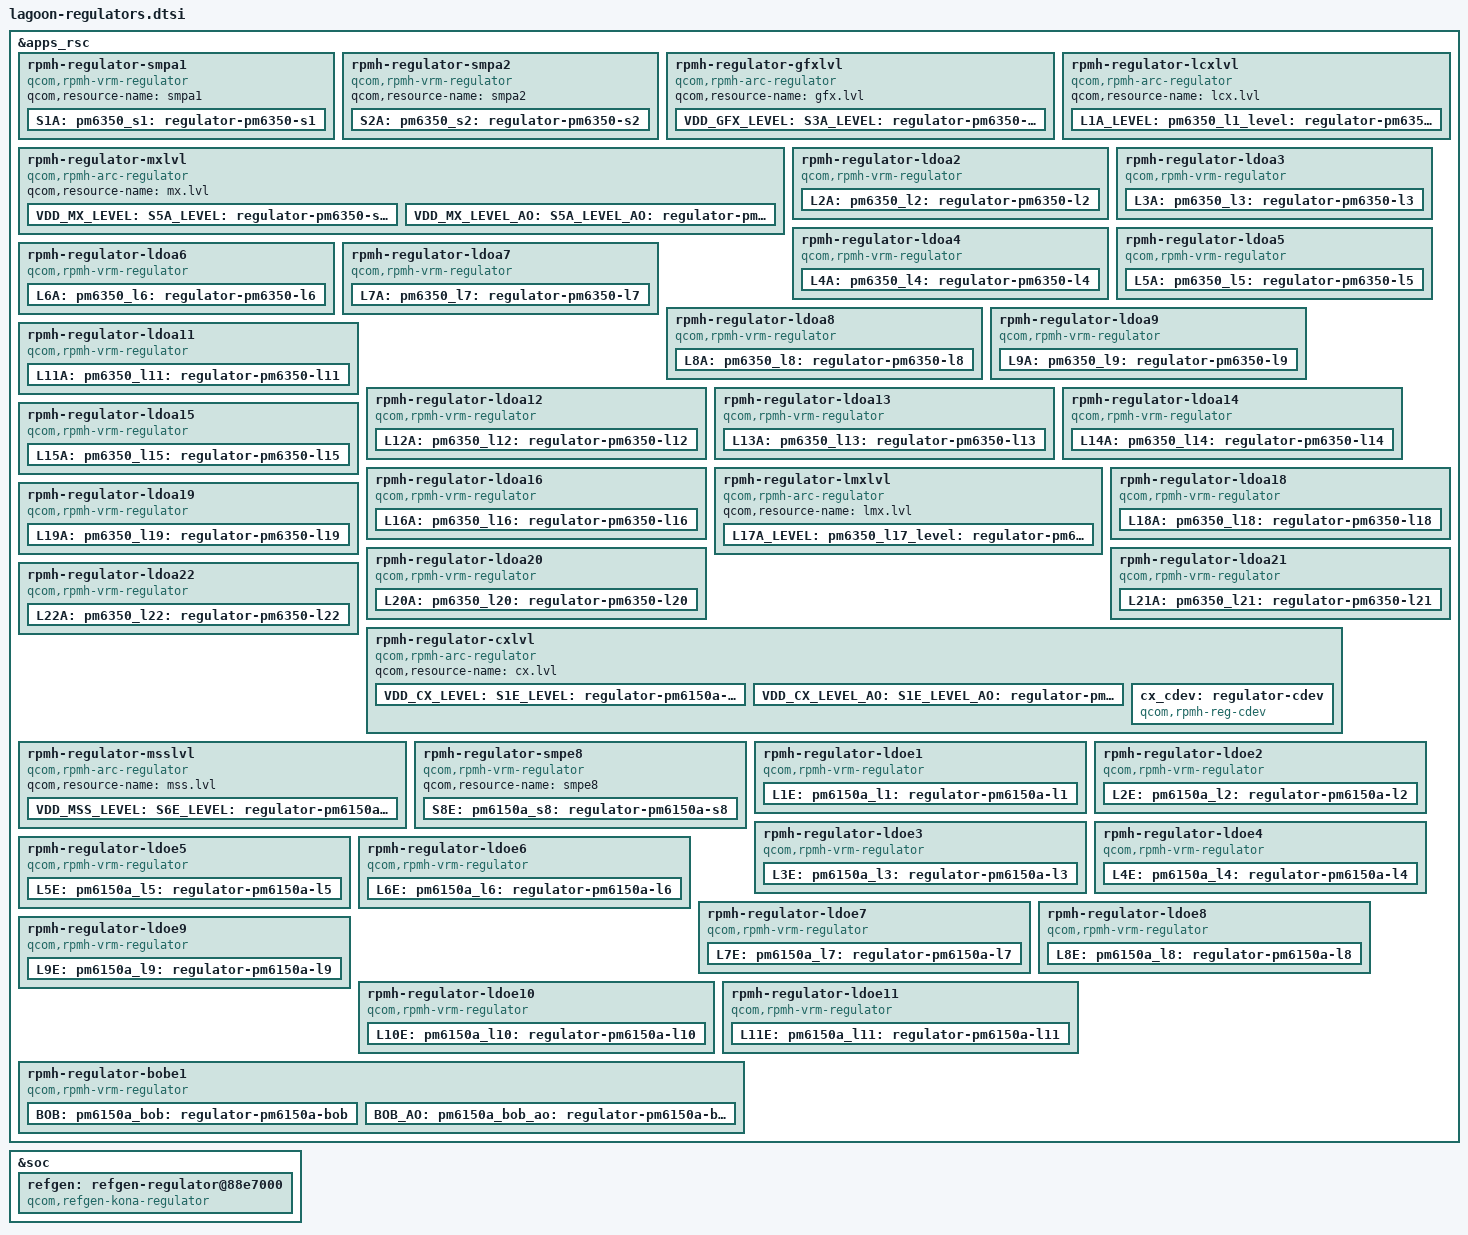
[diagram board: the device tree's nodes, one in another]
#include <dt-bindings/regulator/qcom,rpmh-regulator-levels.h>

&apps_rsc {
	rpmh-regulator-smpa1 {
		compatible = "qcom,rpmh-vrm-regulator";
		qcom,resource-name = "smpa1";
		S1A:
		pm6350_s1: regulator-pm6350-s1 {
			regulator-name = "pm6350_s1";
			qcom,set = <RPMH_REGULATOR_SET_ALL>;
			regulator-min-microvolt = <1000000>;
			regulator-max-microvolt = <1200000>;
			qcom,init-voltage = <1000000>;
		};
	};

	rpmh-regulator-smpa2 {
		compatible = "qcom,rpmh-vrm-regulator";
		qcom,resource-name = "smpa2";
		S2A:
		pm6350_s2: regulator-pm6350-s2 {
			regulator-name = "pm6350_s2";
			qcom,set = <RPMH_REGULATOR_SET_ALL>;
			regulator-min-microvolt = <1503000>;
			regulator-max-microvolt = <2048000>;
			qcom,init-voltage = <1503000>;
		};
	};

	rpmh-regulator-gfxlvl {
		compatible = "qcom,rpmh-arc-regulator";
		qcom,resource-name = "gfx.lvl";
		VDD_GFX_LEVEL:
		S3A_LEVEL:
		pm6350_s3_level: regulator-pm6350-s3-level {
			regulator-name = "pm6350_s3_level";
			qcom,set = <RPMH_REGULATOR_SET_ALL>;
			regulator-min-microvolt =
				<RPMH_REGULATOR_LEVEL_RETENTION>;
			regulator-max-microvolt = <RPMH_REGULATOR_LEVEL_MAX>;
			qcom,init-voltage-level =
				<RPMH_REGULATOR_LEVEL_RETENTION>;
		};
	};

	rpmh-regulator-mxlvl {
		compatible = "qcom,rpmh-arc-regulator";
		qcom,resource-name = "mx.lvl";
		VDD_MX_LEVEL:
		S5A_LEVEL:
		pm6350_s5_level: regulator-pm6350-s5-level {
			regulator-name = "pm6350_s5_level";
			qcom,set = <RPMH_REGULATOR_SET_ALL>;
			regulator-min-microvolt =
				<RPMH_REGULATOR_LEVEL_RETENTION>;
			regulator-max-microvolt = <RPMH_REGULATOR_LEVEL_MAX>;
			qcom,init-voltage-level =
				<RPMH_REGULATOR_LEVEL_RETENTION>;
		};

		VDD_MX_LEVEL_AO:
		S5A_LEVEL_AO:
		pm6350_s5_level_ao: regulator-pm6350-s5-level-ao {
			regulator-name = "pm6350_s5_level_ao";
			qcom,set = <RPMH_REGULATOR_SET_ACTIVE>;
			regulator-min-microvolt =
				<RPMH_REGULATOR_LEVEL_RETENTION>;
			regulator-max-microvolt = <RPMH_REGULATOR_LEVEL_MAX>;
			qcom,init-voltage-level =
				<RPMH_REGULATOR_LEVEL_RETENTION>;
		};
	};

	rpmh-regulator-lcxlvl {
		compatible = "qcom,rpmh-arc-regulator";
		qcom,resource-name = "lcx.lvl";
		L1A_LEVEL:
		pm6350_l1_level: regulator-pm6350-l1-level {
			regulator-name = "pm6350_l1_level";
			qcom,set = <RPMH_REGULATOR_SET_ALL>;
			regulator-min-microvolt =
				<RPMH_REGULATOR_LEVEL_RETENTION>;
			regulator-max-microvolt = <RPMH_REGULATOR_LEVEL_MAX>;
			qcom,init-voltage-level =
				<RPMH_REGULATOR_LEVEL_RETENTION>;
		};
	};

	rpmh-regulator-ldoa2 {
		compatible = "qcom,rpmh-vrm-regulator";
		qcom,resource-name = "ldoa2";
		qcom,regulator-type = "pmic5-ldo";
		qcom,supported-modes =
			<RPMH_REGULATOR_MODE_LPM
			RPMH_REGULATOR_MODE_HPM>;
		qcom,mode-threshold-currents = <0 1>;
		L2A:
		pm6350_l2: regulator-pm6350-l2 {
			regulator-name = "pm6350_l2";
			qcom,set = <RPMH_REGULATOR_SET_ALL>;
			regulator-min-microvolt = <1503000>;
			regulator-max-microvolt = <1980000>;
			qcom,init-voltage = <1503000>;
			qcom,init-mode = <RPMH_REGULATOR_MODE_LPM>;
		};
	};

	rpmh-regulator-ldoa3 {
		compatible = "qcom,rpmh-vrm-regulator";
		qcom,resource-name = "ldoa3";
		qcom,regulator-type = "pmic5-ldo";
		qcom,supported-modes =
			<RPMH_REGULATOR_MODE_LPM
			RPMH_REGULATOR_MODE_HPM>;
		qcom,mode-threshold-currents = <0 1>;
		L3A:
		pm6350_l3: regulator-pm6350-l3 {
			regulator-name = "pm6350_l3";
			qcom,set = <RPMH_REGULATOR_SET_ALL>;
			regulator-min-microvolt = <2700000>;
			regulator-max-microvolt = <3300000>;
			qcom,init-voltage = <2700000>;
			qcom,init-mode = <RPMH_REGULATOR_MODE_LPM>;
		};
	};

	rpmh-regulator-ldoa4 {
		compatible = "qcom,rpmh-vrm-regulator";
		qcom,resource-name = "ldoa4";
		qcom,regulator-type = "pmic5-ldo";
		qcom,supported-modes =
			<RPMH_REGULATOR_MODE_LPM
			RPMH_REGULATOR_MODE_HPM>;
		qcom,mode-threshold-currents = <0 1>;
		L4A:
		pm6350_l4: regulator-pm6350-l4 {
			regulator-name = "pm6350_l4";
			qcom,set = <RPMH_REGULATOR_SET_ALL>;
			regulator-min-microvolt = <352000>;
			regulator-max-microvolt = <801000>;
			qcom,init-voltage = <352000>;
			qcom,init-mode = <RPMH_REGULATOR_MODE_LPM>;
		};
	};

	rpmh-regulator-ldoa5 {
		compatible = "qcom,rpmh-vrm-regulator";
		qcom,resource-name = "ldoa5";
		qcom,regulator-type = "pmic5-ldo";
		qcom,supported-modes =
			<RPMH_REGULATOR_MODE_LPM
			RPMH_REGULATOR_MODE_HPM>;
		qcom,mode-threshold-currents = <0 1>;
		L5A:
		pm6350_l5: regulator-pm6350-l5 {
			regulator-name = "pm6350_l5";
			qcom,set = <RPMH_REGULATOR_SET_ALL>;
			regulator-min-microvolt = <1503000>;
			regulator-max-microvolt = <1980000>;
			qcom,init-voltage = <1503000>;
			qcom,init-mode = <RPMH_REGULATOR_MODE_LPM>;
		};
	};

	rpmh-regulator-ldoa6 {
		compatible = "qcom,rpmh-vrm-regulator";
		qcom,resource-name = "ldoa6";
		qcom,regulator-type = "pmic5-ldo";
		qcom,supported-modes =
			<RPMH_REGULATOR_MODE_LPM
			RPMH_REGULATOR_MODE_HPM>;
		qcom,mode-threshold-currents = <0 1>;
		L6A:
		pm6350_l6: regulator-pm6350-l6 {
			regulator-name = "pm6350_l6";
			qcom,set = <RPMH_REGULATOR_SET_ALL>;
			regulator-min-microvolt = <1710000>;
			regulator-max-microvolt = <3544000>;
			qcom,init-voltage = <1710000>;
			qcom,init-mode = <RPMH_REGULATOR_MODE_LPM>;
		};
	};

	rpmh-regulator-ldoa7 {
		compatible = "qcom,rpmh-vrm-regulator";
		qcom,resource-name = "ldoa7";
		qcom,regulator-type = "pmic5-ldo";
		qcom,supported-modes =
			<RPMH_REGULATOR_MODE_LPM
			RPMH_REGULATOR_MODE_HPM>;
		qcom,mode-threshold-currents = <0 1>;
		L7A:
		pm6350_l7: regulator-pm6350-l7 {
			regulator-name = "pm6350_l7";
			qcom,set = <RPMH_REGULATOR_SET_ALL>;
			regulator-min-microvolt = <1620000>;
			regulator-max-microvolt = <1980000>;
			qcom,init-voltage = <1620000>;
			qcom,init-mode = <RPMH_REGULATOR_MODE_LPM>;
		};
	};

	rpmh-regulator-ldoa8 {
		compatible = "qcom,rpmh-vrm-regulator";
		qcom,resource-name = "ldoa8";
		qcom,regulator-type = "pmic5-ldo";
		qcom,supported-modes =
			<RPMH_REGULATOR_MODE_LPM
			RPMH_REGULATOR_MODE_HPM>;
		qcom,mode-threshold-currents = <0 1>;
		L8A:
		pm6350_l8: regulator-pm6350-l8 {
			regulator-name = "pm6350_l8";
			qcom,set = <RPMH_REGULATOR_SET_ALL>;
			regulator-min-microvolt = <2500000>;
			regulator-max-microvolt = <3544000>;
			qcom,init-voltage = <2500000>;
			qcom,init-mode = <RPMH_REGULATOR_MODE_LPM>;
		};
	};

	rpmh-regulator-ldoa9 {
		compatible = "qcom,rpmh-vrm-regulator";
		qcom,resource-name = "ldoa9";
		qcom,regulator-type = "pmic5-ldo";
		qcom,supported-modes =
			<RPMH_REGULATOR_MODE_LPM
			RPMH_REGULATOR_MODE_HPM>;
		qcom,mode-threshold-currents = <0 1>;
		L9A:
		pm6350_l9: regulator-pm6350-l9 {
			regulator-name = "pm6350_l9";
			qcom,set = <RPMH_REGULATOR_SET_ALL>;
			regulator-min-microvolt = <1650000>;
			regulator-max-microvolt = <3401000>;
			qcom,init-voltage = <1650000>;
			qcom,init-mode = <RPMH_REGULATOR_MODE_LPM>;
		};
	};

	rpmh-regulator-ldoa11 {
		compatible = "qcom,rpmh-vrm-regulator";
		qcom,resource-name = "ldoa11";
		qcom,regulator-type = "pmic5-ldo";
		qcom,supported-modes =
			<RPMH_REGULATOR_MODE_LPM
			RPMH_REGULATOR_MODE_HPM>;
		qcom,mode-threshold-currents = <0 1>;
		L11A:
		pm6350_l11: regulator-pm6350-l11 {
			regulator-name = "pm6350_l11";
			qcom,set = <RPMH_REGULATOR_SET_ALL>;
			regulator-min-microvolt = <1800000>;
			regulator-max-microvolt = <2000000>;
			qcom,init-voltage = <1800000>;
			qcom,init-mode = <RPMH_REGULATOR_MODE_LPM>;
		};
	};

	rpmh-regulator-ldoa12 {
		compatible = "qcom,rpmh-vrm-regulator";
		qcom,resource-name = "ldoa12";
		qcom,regulator-type = "pmic5-ldo";
		qcom,supported-modes =
			<RPMH_REGULATOR_MODE_LPM
			RPMH_REGULATOR_MODE_HPM>;
		qcom,mode-threshold-currents = <0 1>;
		L12A:
		pm6350_l12: regulator-pm6350-l12 {
			regulator-name = "pm6350_l12";
			qcom,set = <RPMH_REGULATOR_SET_ALL>;
			regulator-min-microvolt = <1620000>;
			regulator-max-microvolt = <1980000>;
			qcom,init-voltage = <1620000>;
			qcom,init-mode = <RPMH_REGULATOR_MODE_LPM>;
		};
	};

	rpmh-regulator-ldoa13 {
		compatible = "qcom,rpmh-vrm-regulator";
		qcom,resource-name = "ldoa13";
		qcom,regulator-type = "pmic5-ldo";
		qcom,supported-modes =
			<RPMH_REGULATOR_MODE_LPM
			RPMH_REGULATOR_MODE_HPM>;
		qcom,mode-threshold-currents = <0 1>;
		L13A:
		pm6350_l13: regulator-pm6350-l13 {
			regulator-name = "pm6350_l13";
			qcom,set = <RPMH_REGULATOR_SET_ALL>;
			regulator-min-microvolt = <570000>;
			regulator-max-microvolt = <650000>;
			qcom,init-voltage = <570000>;
			qcom,init-mode = <RPMH_REGULATOR_MODE_LPM>;
		};
	};

	rpmh-regulator-ldoa14 {
		compatible = "qcom,rpmh-vrm-regulator";
		qcom,resource-name = "ldoa14";
		qcom,regulator-type = "pmic5-ldo";
		qcom,supported-modes =
			<RPMH_REGULATOR_MODE_LPM
			RPMH_REGULATOR_MODE_HPM>;
		qcom,mode-threshold-currents = <0 1>;
		L14A:
		pm6350_l14: regulator-pm6350-l14 {
			regulator-name = "pm6350_l14";
			qcom,set = <RPMH_REGULATOR_SET_ALL>;
			regulator-min-microvolt = <1700000>;
			regulator-max-microvolt = <1900000>;
			qcom,init-voltage = <1700000>;
			qcom,init-mode = <RPMH_REGULATOR_MODE_LPM>;
		};
	};

	rpmh-regulator-ldoa15 {
		compatible = "qcom,rpmh-vrm-regulator";
		qcom,resource-name = "ldoa15";
		qcom,regulator-type = "pmic5-ldo";
		qcom,supported-modes =
			<RPMH_REGULATOR_MODE_LPM
			RPMH_REGULATOR_MODE_HPM>;
		qcom,mode-threshold-currents = <0 1>;
		L15A:
		pm6350_l15: regulator-pm6350-l15 {
			regulator-name = "pm6350_l15";
			qcom,set = <RPMH_REGULATOR_SET_ALL>;
			regulator-min-microvolt = <1100000>;
			regulator-max-microvolt = <1305000>;
			qcom,init-voltage = <1100000>;
			qcom,init-mode = <RPMH_REGULATOR_MODE_LPM>;
		};
	};

	rpmh-regulator-ldoa16 {
		compatible = "qcom,rpmh-vrm-regulator";
		qcom,resource-name = "ldoa16";
		qcom,regulator-type = "pmic5-ldo";
		qcom,supported-modes =
			<RPMH_REGULATOR_MODE_LPM
			RPMH_REGULATOR_MODE_HPM>;
		qcom,mode-threshold-currents = <0 1>;
		L16A:
		pm6350_l16: regulator-pm6350-l16 {
			regulator-name = "pm6350_l16";
			qcom,set = <RPMH_REGULATOR_SET_ALL>;
			regulator-min-microvolt = <830000>;
			regulator-max-microvolt = <921000>;
			qcom,init-voltage = <830000>;
			qcom,init-mode = <RPMH_REGULATOR_MODE_LPM>;
		};
	};

	rpmh-regulator-lmxlvl {
		compatible = "qcom,rpmh-arc-regulator";
		qcom,resource-name = "lmx.lvl";
		L17A_LEVEL:
		pm6350_l17_level: regulator-pm6350-l17-level {
			regulator-name = "pm6350_l17_level";
			qcom,set = <RPMH_REGULATOR_SET_ALL>;
			regulator-min-microvolt =
				<RPMH_REGULATOR_LEVEL_RETENTION>;
			regulator-max-microvolt = <RPMH_REGULATOR_LEVEL_MAX>;
			qcom,init-voltage-level =
				<RPMH_REGULATOR_LEVEL_RETENTION>;
		};
	};

	rpmh-regulator-ldoa18 {
		compatible = "qcom,rpmh-vrm-regulator";
		qcom,resource-name = "ldoa18";
		qcom,regulator-type = "pmic5-ldo";
		qcom,supported-modes =
			<RPMH_REGULATOR_MODE_LPM
			RPMH_REGULATOR_MODE_HPM>;
		qcom,mode-threshold-currents = <0 1>;
		L18A:
		pm6350_l18: regulator-pm6350-l18 {
			regulator-name = "pm6350_l18";
			qcom,set = <RPMH_REGULATOR_SET_ALL>;
			regulator-min-microvolt = <788000>;
			regulator-max-microvolt = <1049000>;
			qcom,init-voltage = <788000>;
			qcom,init-mode = <RPMH_REGULATOR_MODE_LPM>;
		};
	};

	rpmh-regulator-ldoa19 {
		compatible = "qcom,rpmh-vrm-regulator";
		qcom,resource-name = "ldoa19";
		qcom,regulator-type = "pmic5-ldo";
		qcom,supported-modes =
			<RPMH_REGULATOR_MODE_LPM
			RPMH_REGULATOR_MODE_HPM>;
		qcom,mode-threshold-currents = <0 1>;
		L19A:
		pm6350_l19: regulator-pm6350-l19 {
			regulator-name = "pm6350_l19";
			qcom,set = <RPMH_REGULATOR_SET_ALL>;
			regulator-min-microvolt = <1080000>;
			regulator-max-microvolt = <1305000>;
			qcom,init-voltage = <1080000>;
			qcom,init-mode = <RPMH_REGULATOR_MODE_LPM>;
		};
	};

	rpmh-regulator-ldoa20 {
		compatible = "qcom,rpmh-vrm-regulator";
		qcom,resource-name = "ldoa20";
		qcom,regulator-type = "pmic5-ldo";
		qcom,supported-modes =
			<RPMH_REGULATOR_MODE_LPM
			RPMH_REGULATOR_MODE_HPM>;
		qcom,mode-threshold-currents = <0 1>;
		L20A:
		pm6350_l20: regulator-pm6350-l20 {
			regulator-name = "pm6350_l20";
			qcom,set = <RPMH_REGULATOR_SET_ALL>;
			regulator-min-microvolt = <530000>;
			regulator-max-microvolt = <801000>;
			qcom,init-voltage = <530000>;
			qcom,init-mode = <RPMH_REGULATOR_MODE_LPM>;
		};
	};

	rpmh-regulator-ldoa21 {
		compatible = "qcom,rpmh-vrm-regulator";
		qcom,resource-name = "ldoa21";
		qcom,regulator-type = "pmic5-ldo";
		qcom,supported-modes =
			<RPMH_REGULATOR_MODE_LPM
			RPMH_REGULATOR_MODE_HPM>;
		qcom,mode-threshold-currents = <0 1>;
		L21A:
		pm6350_l21: regulator-pm6350-l21 {
			regulator-name = "pm6350_l21";
			qcom,set = <RPMH_REGULATOR_SET_ALL>;
			regulator-min-microvolt = <751000>;
			regulator-max-microvolt = <825000>;
			qcom,init-voltage = <751000>;
			qcom,init-mode = <RPMH_REGULATOR_MODE_LPM>;
		};
	};

	rpmh-regulator-ldoa22 {
		compatible = "qcom,rpmh-vrm-regulator";
		qcom,resource-name = "ldoa22";
		qcom,regulator-type = "pmic5-ldo";
		qcom,supported-modes =
			<RPMH_REGULATOR_MODE_LPM
			RPMH_REGULATOR_MODE_HPM>;
		qcom,mode-threshold-currents = <0 1>;
		L22A:
		pm6350_l22: regulator-pm6350-l22 {
			regulator-name = "pm6350_l22";
			qcom,set = <RPMH_REGULATOR_SET_ALL>;
			regulator-min-microvolt = <1080000>;
			regulator-max-microvolt = <1305000>;
			qcom,init-voltage = <1080000>;
			qcom,init-mode = <RPMH_REGULATOR_MODE_LPM>;
		};
	};

	rpmh-regulator-cxlvl {
		compatible = "qcom,rpmh-arc-regulator";
		qcom,resource-name = "cx.lvl";
		VDD_CX_LEVEL:
		S1E_LEVEL:
		pm6150a_s1_level: regulator-pm6150a-s1-level {
			regulator-name = "pm6150a_s1_level";
			qcom,set = <RPMH_REGULATOR_SET_ALL>;
			regulator-min-microvolt =
				<RPMH_REGULATOR_LEVEL_RETENTION>;
			regulator-max-microvolt = <RPMH_REGULATOR_LEVEL_MAX>;
			qcom,init-voltage-level =
				<RPMH_REGULATOR_LEVEL_RETENTION>;
			qcom,min-dropout-voltage-level = <(-1)>;
		};

		VDD_CX_LEVEL_AO:
		S1E_LEVEL_AO:
		pm6150a_s1_level_ao: regulator-pm6150a-s1-level-ao {
			regulator-name = "pm6150a_s1_level_ao";
			qcom,set = <RPMH_REGULATOR_SET_ACTIVE>;
			regulator-min-microvolt =
				<RPMH_REGULATOR_LEVEL_RETENTION>;
			regulator-max-microvolt = <RPMH_REGULATOR_LEVEL_MAX>;
			qcom,init-voltage-level =
				<RPMH_REGULATOR_LEVEL_RETENTION>;
			qcom,min-dropout-voltage-level = <(-1)>;
		};

		cx_cdev: regulator-cdev {
			compatible = "qcom,rpmh-reg-cdev";
			mboxes = <&qmp_aop 0>;
			qcom,reg-resource-name = "cx";
			#cooling-cells = <2>;
		};
	};

	rpmh-regulator-msslvl {
		compatible = "qcom,rpmh-arc-regulator";
		qcom,resource-name = "mss.lvl";
		VDD_MSS_LEVEL:
		S6E_LEVEL:
		pm6150a_s6_level: regulator-pm6150a-s6-level {
			regulator-name = "pm6150a_s6_level";
			qcom,set = <RPMH_REGULATOR_SET_ALL>;
			regulator-min-microvolt =
				<RPMH_REGULATOR_LEVEL_RETENTION>;
			regulator-max-microvolt = <RPMH_REGULATOR_LEVEL_MAX>;
			qcom,init-voltage-level =
				<RPMH_REGULATOR_LEVEL_RETENTION>;
		};
	};

	rpmh-regulator-smpe8 {
		compatible = "qcom,rpmh-vrm-regulator";
		qcom,resource-name = "smpe8";
		S8E:
		pm6150a_s8: regulator-pm6150a-s8 {
			regulator-name = "pm6150a_s8";
			qcom,set = <RPMH_REGULATOR_SET_ALL>;
			regulator-min-microvolt = <313000>;
			regulator-max-microvolt = <1395000>;
			qcom,init-voltage = <313000>;
		};
	};

	rpmh-regulator-ldoe1 {
		compatible = "qcom,rpmh-vrm-regulator";
		qcom,resource-name = "ldoe1";
		qcom,regulator-type = "pmic5-ldo";
		qcom,supported-modes =
			<RPMH_REGULATOR_MODE_LPM
			RPMH_REGULATOR_MODE_HPM>;
		qcom,mode-threshold-currents = <0 1>;
		L1E:
		pm6150a_l1: regulator-pm6150a-l1 {
			regulator-name = "pm6150a_l1";
			qcom,set = <RPMH_REGULATOR_SET_ALL>;
			regulator-min-microvolt = <1620000>;
			regulator-max-microvolt = <1980000>;
			qcom,init-voltage = <1620000>;
			qcom,init-mode = <RPMH_REGULATOR_MODE_LPM>;
		};
	};

	rpmh-regulator-ldoe2 {
		compatible = "qcom,rpmh-vrm-regulator";
		qcom,resource-name = "ldoe2";
		qcom,regulator-type = "pmic5-ldo";
		qcom,supported-modes =
			<RPMH_REGULATOR_MODE_LPM
			RPMH_REGULATOR_MODE_HPM>;
		qcom,mode-threshold-currents = <0 1>;
		L2E:
		pm6150a_l2: regulator-pm6150a-l2 {
			regulator-name = "pm6150a_l2";
			qcom,set = <RPMH_REGULATOR_SET_ALL>;
			regulator-min-microvolt = <1170000>;
			regulator-max-microvolt = <1305000>;
			qcom,init-voltage = <1170000>;
			qcom,init-mode = <RPMH_REGULATOR_MODE_LPM>;
		};
	};

	rpmh-regulator-ldoe3 {
		compatible = "qcom,rpmh-vrm-regulator";
		qcom,resource-name = "ldoe3";
		qcom,regulator-type = "pmic5-ldo";
		qcom,supported-modes =
			<RPMH_REGULATOR_MODE_LPM
			RPMH_REGULATOR_MODE_HPM>;
		qcom,mode-threshold-currents = <0 1>;
		L3E:
		pm6150a_l3: regulator-pm6150a-l3 {
			regulator-name = "pm6150a_l3";
			qcom,set = <RPMH_REGULATOR_SET_ALL>;
			regulator-min-microvolt = <1100000>;
			regulator-max-microvolt = <1299000>;
			qcom,init-voltage = <1100000>;
			qcom,init-mode = <RPMH_REGULATOR_MODE_LPM>;
		};
	};

	rpmh-regulator-ldoe4 {
		compatible = "qcom,rpmh-vrm-regulator";
		qcom,resource-name = "ldoe4";
		qcom,regulator-type = "pmic5-ldo";
		qcom,supported-modes =
			<RPMH_REGULATOR_MODE_LPM
			RPMH_REGULATOR_MODE_HPM>;
		qcom,mode-threshold-currents = <0 1>;
		L4E:
		pm6150a_l4: regulator-pm6150a-l4 {
			regulator-name = "pm6150a_l4";
			qcom,set = <RPMH_REGULATOR_SET_ALL>;
			regulator-min-microvolt = <1620000>;
			regulator-max-microvolt = <3300000>;
			qcom,init-voltage = <1620000>;
			qcom,init-mode = <RPMH_REGULATOR_MODE_LPM>;
		};
	};

	rpmh-regulator-ldoe5 {
		compatible = "qcom,rpmh-vrm-regulator";
		qcom,resource-name = "ldoe5";
		qcom,regulator-type = "pmic5-ldo";
		qcom,supported-modes =
			<RPMH_REGULATOR_MODE_LPM
			RPMH_REGULATOR_MODE_HPM>;
		qcom,mode-threshold-currents = <0 1>;
		L5E:
		pm6150a_l5: regulator-pm6150a-l5 {
			regulator-name = "pm6150a_l5";
			qcom,set = <RPMH_REGULATOR_SET_ALL>;
			regulator-min-microvolt = <1620000>;
			regulator-max-microvolt = <3300000>;
			qcom,init-voltage = <1620000>;
			qcom,init-mode = <RPMH_REGULATOR_MODE_LPM>;
		};
	};

	rpmh-regulator-ldoe6 {
		compatible = "qcom,rpmh-vrm-regulator";
		qcom,resource-name = "ldoe6";
		qcom,regulator-type = "pmic5-ldo";
		qcom,supported-modes =
			<RPMH_REGULATOR_MODE_LPM
			RPMH_REGULATOR_MODE_HPM>;
		qcom,mode-threshold-currents = <0 1>;
		L6E:
		pm6150a_l6: regulator-pm6150a-l6 {
			regulator-name = "pm6150a_l6";
			qcom,set = <RPMH_REGULATOR_SET_ALL>;
			regulator-min-microvolt = <1700000>;
			regulator-max-microvolt = <3544000>;
			qcom,init-voltage = <1700000>;
			qcom,init-mode = <RPMH_REGULATOR_MODE_LPM>;
		};
	};

	rpmh-regulator-ldoe7 {
		compatible = "qcom,rpmh-vrm-regulator";
		qcom,resource-name = "ldoe7";
		qcom,regulator-type = "pmic5-ldo";
		qcom,supported-modes =
			<RPMH_REGULATOR_MODE_LPM
			RPMH_REGULATOR_MODE_HPM>;
		qcom,mode-threshold-currents = <0 1>;
		L7E:
		pm6150a_l7: regulator-pm6150a-l7 {
			regulator-name = "pm6150a_l7";
			qcom,set = <RPMH_REGULATOR_SET_ALL>;
			regulator-min-microvolt = <2700000>;
			regulator-max-microvolt = <3544000>;
			qcom,init-voltage = <2700000>;
			qcom,init-mode = <RPMH_REGULATOR_MODE_LPM>;
		};
	};

	rpmh-regulator-ldoe8 {
		compatible = "qcom,rpmh-vrm-regulator";
		qcom,resource-name = "ldoe8";
		qcom,regulator-type = "pmic5-ldo";
		qcom,supported-modes =
			<RPMH_REGULATOR_MODE_LPM
			RPMH_REGULATOR_MODE_HPM>;
		qcom,mode-threshold-currents = <0 1>;
		L8E:
		pm6150a_l8: regulator-pm6150a-l8 {
			regulator-name = "pm6150a_l8";
			qcom,set = <RPMH_REGULATOR_SET_ALL>;
			regulator-min-microvolt = <1620000>;
			regulator-max-microvolt = <2000000>;
			qcom,init-voltage = <1620000>;
			qcom,init-mode = <RPMH_REGULATOR_MODE_LPM>;
		};
	};

	rpmh-regulator-ldoe9 {
		compatible = "qcom,rpmh-vrm-regulator";
		qcom,resource-name = "ldoe9";
		qcom,regulator-type = "pmic5-ldo";
		qcom,supported-modes =
			<RPMH_REGULATOR_MODE_LPM
			RPMH_REGULATOR_MODE_HPM>;
		qcom,mode-threshold-currents = <0 1>;
		L9E:
		pm6150a_l9: regulator-pm6150a-l9 {
			regulator-name = "pm6150a_l9";
			qcom,set = <RPMH_REGULATOR_SET_ALL>;
			regulator-min-microvolt = <2700000>;
			regulator-max-microvolt = <3544000>;
			qcom,init-voltage = <2700000>;
			qcom,init-mode = <RPMH_REGULATOR_MODE_LPM>;
		};
	};

	rpmh-regulator-ldoe10 {
		compatible = "qcom,rpmh-vrm-regulator";
		qcom,resource-name = "ldoe10";
		qcom,regulator-type = "pmic5-ldo";
		qcom,supported-modes =
			<RPMH_REGULATOR_MODE_LPM
			RPMH_REGULATOR_MODE_HPM>;
		qcom,mode-threshold-currents = <0 1>;
		L10E:
		pm6150a_l10: regulator-pm6150a-l10 {
			regulator-name = "pm6150a_l10";
			qcom,set = <RPMH_REGULATOR_SET_ALL>;
			regulator-min-microvolt = <3000000>;
			regulator-max-microvolt = <3401000>;
			qcom,init-voltage = <3000000>;
			qcom,init-mode = <RPMH_REGULATOR_MODE_LPM>;
		};
	};

	rpmh-regulator-ldoe11 {
		compatible = "qcom,rpmh-vrm-regulator";
		qcom,resource-name = "ldoe11";
		qcom,regulator-type = "pmic5-ldo";
		qcom,supported-modes =
			<RPMH_REGULATOR_MODE_LPM
			RPMH_REGULATOR_MODE_HPM>;
		qcom,mode-threshold-currents = <0 1>;
		L11E:
		pm6150a_l11: regulator-pm6150a-l11 {
			regulator-name = "pm6150a_l11";
			qcom,set = <RPMH_REGULATOR_SET_ALL>;
			regulator-min-microvolt = <3000000>;
			regulator-max-microvolt = <3401000>;
			qcom,init-voltage = <3000000>;
			qcom,init-mode = <RPMH_REGULATOR_MODE_LPM>;
		};
	};

	rpmh-regulator-bobe1 {
		compatible = "qcom,rpmh-vrm-regulator";
		qcom,resource-name = "bobe1";
		qcom,regulator-type = "pmic5-bob";
		qcom,supported-modes =
			<RPMH_REGULATOR_MODE_PASS
			RPMH_REGULATOR_MODE_LPM
			RPMH_REGULATOR_MODE_HPM>;
		qcom,mode-threshold-currents = <0 1000000 2000000>;
		qcom,send-defaults;
		BOB:
		pm6150a_bob: regulator-pm6150a-bob {
			regulator-name = "pm6150a_bob";
			qcom,set = <RPMH_REGULATOR_SET_ALL>;
			regulator-min-microvolt = <1620000>;
			regulator-max-microvolt = <5492000>;
			qcom,init-voltage = <1620000>;
			qcom,init-mode = <RPMH_REGULATOR_MODE_PASS>;
		};

		BOB_AO:
		pm6150a_bob_ao: regulator-pm6150a-bob-ao {
			regulator-name = "pm6150a_bob_ao";
			qcom,set = <RPMH_REGULATOR_SET_ACTIVE>;
			regulator-min-microvolt = <1620000>;
			regulator-max-microvolt = <5492000>;
			qcom,init-voltage = <1620000>;
			qcom,init-mode = <RPMH_REGULATOR_MODE_AUTO>;
		};
	};
};

&soc {
	refgen: refgen-regulator@88e7000 {
		compatible = "qcom,refgen-kona-regulator";
		reg = <0x88e7000 0x60>;
		regulator-name = "refgen";
		regulator-enable-ramp-delay = <5>;
	};
};
